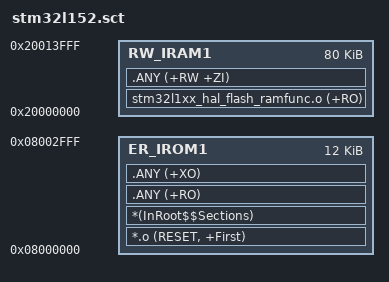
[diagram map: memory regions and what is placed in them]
; *************************************************************
; *** Scatter-Loading Description File generated by uVision ***
; *************************************************************

LR_IROM1 0x08000000 0x00003000  {    ; load region size_region
  ER_IROM1 0x08000000 0x00003000  {  ; load address = execution address
   *.o (RESET, +First)
   *(InRoot$$Sections)
   .ANY (+RO)
   .ANY (+XO)
  }
  RW_IRAM1 0x20000000 0x00014000  {  ; RW data
   stm32l1xx_hal_flash_ramfunc.o (+RO)
   .ANY (+RW +ZI)
  }
}

